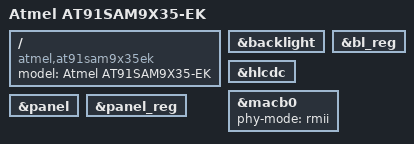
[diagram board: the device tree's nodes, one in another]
/dts-v1/;
#include "at91sam9x35.dtsi"
#include "at91sam9x5dm.dtsi"
#include "at91sam9x5ek.dtsi"
/ {
	model = "Atmel AT91SAM9X35-EK";
	compatible = "atmel,at91sam9x35ek", "atmel,at91sam9x5ek", "atmel,at91sam9x5", "atmel,at91sam9";
};
&backlight {
	status = "okay";
};
&bl_reg {
	status = "okay";
};
&hlcdc {
	status = "okay";
};
&macb0 {
	phy-mode = "rmii";
	status = "okay";
};
&panel {
	status = "okay";
};
&panel_reg {
	status = "okay";
};
